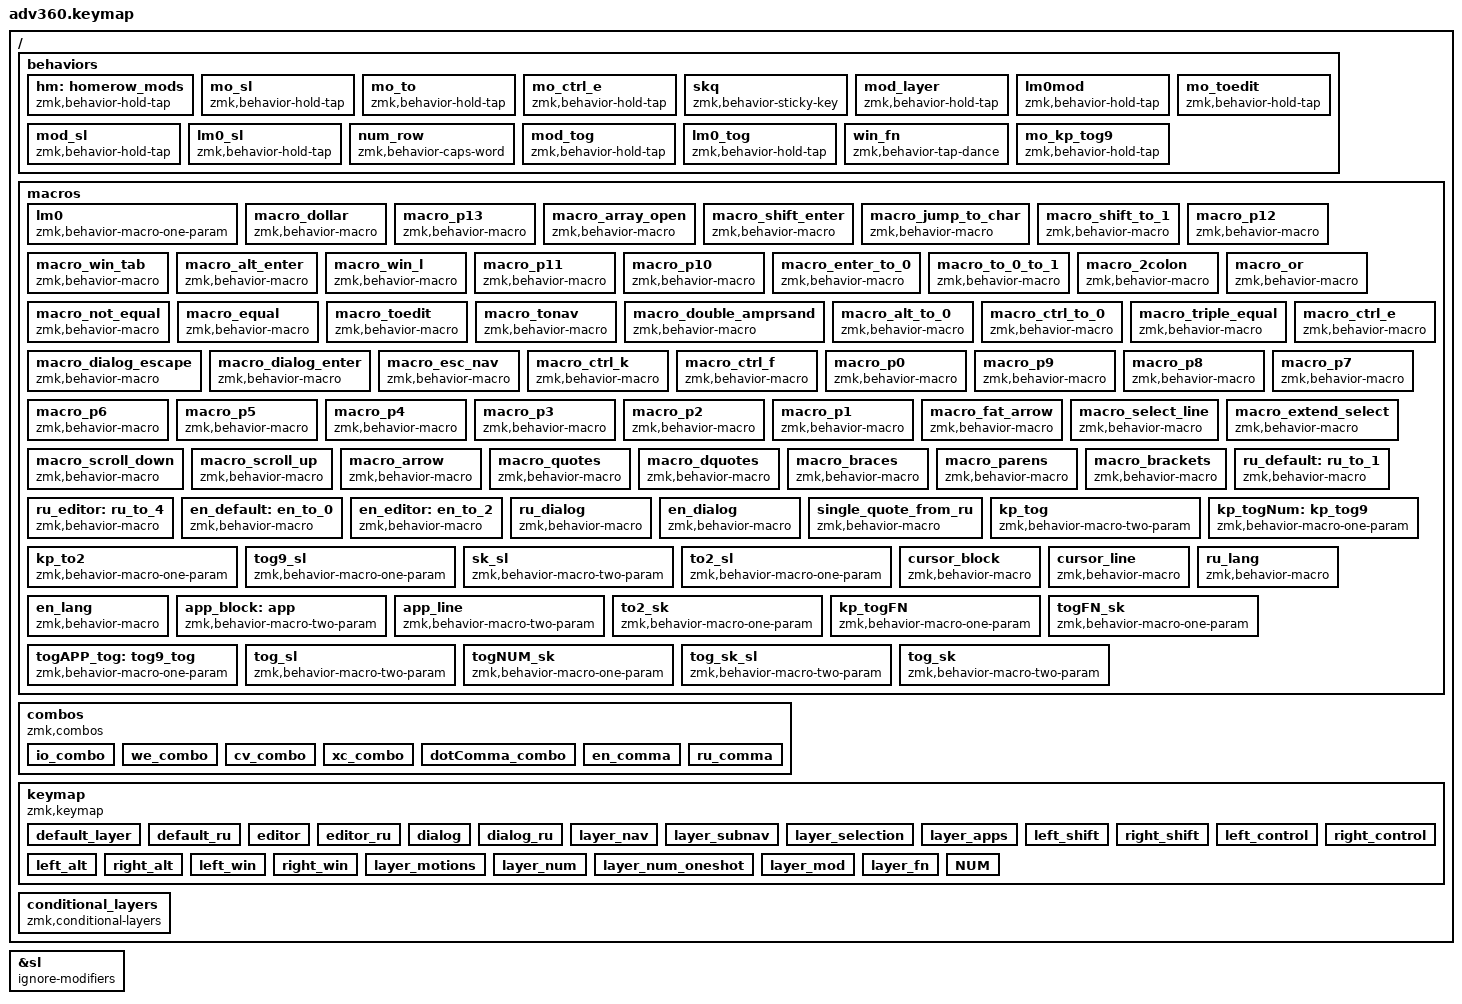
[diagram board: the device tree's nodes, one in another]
/*
 * Copyright (c) 2020 The ZMK Contributors
 *
 * SPDX-License-Identifier: MIT
 */
/* THIS FILE WAS GENERATED!
 *
 * This file was generated automatically. You may or may not want to
 * edit it directly.
 */

#include <dt-bindings/zmk/stp.h>
#include <behaviors.dtsi>
#include <dt-bindings/zmk/backlight.h>
#include <dt-bindings/zmk/bt.h>
#include <dt-bindings/zmk/keys.h>
#include <dt-bindings/zmk/rgb.h>

&sl { ignore-modifiers; };

/ {
    behaviors {
        //#include "macros.dtsi"

        #include "version.dtsi"

        hm: homerow_mods {
            compatible = "zmk,behavior-hold-tap";
            label = "HOMEROW_MODS";
            #binding-cells = <2>;
            tapping-term-ms = <200>;
            quick_tap_ms = <175>;
            flavor = "tap-preferred";
            bindings = <&kp>, <&kp>;
        };

        mo_sl: mo_sl {
            compatible = "zmk,behavior-hold-tap";
            label = "MO_SL";
            #binding-cells = <2>;
            tapping-term-ms = <200>;
            flavor = "tap-preferred";
            bindings = <&mo>, <&sl>;
        };

        mo_to: mo_to {
            compatible = "zmk,behavior-hold-tap";
            label = "MO_TO";
            #binding-cells = <2>;
            tapping-term-ms = <200>;
            quick_tap_ms = <175>;
            flavor = "tap-preferred";
            bindings = <&mo>, <&to>;
        };

        mo_ctrl_e: mo_ctrl_e {
            compatible = "zmk,behavior-hold-tap";
            label = "MO_CTRL_E";
            #binding-cells = <2>;
            tapping-term-ms = <200>;
            quick_tap_ms = <175>;
            flavor = "tap-preferred";
            bindings = <&mo>, <&macro_ctrl_e>;
        };

        skq: skq {
            compatible = "zmk,behavior-sticky-key";
            label = "SKQ";
            bindings = <&kp>;
            #binding-cells = <1>;
            quick-release;
            ignore-modifiers;
            release-after-ms = <1000>;
        };

        mod_layer: mod_layer {
            compatible = "zmk,behavior-hold-tap";
            label = "MOD_LAYER_ENHANCED";
            #binding-cells = <2>;
            tapping-term-ms = <200>;
            quick-tap-ms = <0>;
            flavor = "hold-preferred";
            bindings = <&mo>, <&kp>;

            hold-trigger-key-positions = <71 72 73 74 61 62 63 64 65 70 49 56>;
        };

        lm0mod: lm0mod {
            compatible = "zmk,behavior-hold-tap";
            label = "LM_MOD_0";
            #binding-cells = <2>;
            tapping-term-ms = <200>;
            quick_tap_ms = <175>;
            flavor = "tap-preferred";
            bindings = <&lm0>, <&kp>;
        };

        mo_toedit: mo_toedit {
            compatible = "zmk,behavior-hold-tap";
            label = "MO_TOEDIT";
            #binding-cells = <2>;
            tapping-term-ms = <200>;
            quick_tap_ms = <175>;
            flavor = "tap-preferred";
            bindings = <&mo>, <&macro_toedit>;
        };

        mod_sl: mod_sl {
            compatible = "zmk,behavior-hold-tap";
            label = "MOD_SL";
            bindings = <&kp>, <&sl>;

            #binding-cells = <2>;
            tapping-term-ms = <200>;
            flavor = "tap-preferred";
        };

        lm0_sl: lm0_sl {
            compatible = "zmk,behavior-hold-tap";
            label = "LM0_SL";
            bindings = <&lm0>, <&sl>;

            #binding-cells = <2>;
            flavor = "tap-preferred";
            tapping-term-ms = <200>;
        };

        num_row: num_row {
            compatible = "zmk,behavior-caps-word";
            label = "NUM_ROW";
            #binding-cells = <0>;
            continue-list = <N1 N2 N3 N4 N5 N6 N7 N8 N9 N0>;
            mods = <(MOD_LCTL|MOD_LSFT|MOD_LALT|MOD_LGUI|MOD_RCTL|MOD_RSFT|MOD_RALT|MOD_RGUI)>;
        };

        mod_tog: mod_tog {
            compatible = "zmk,behavior-hold-tap";
            label = "MOD_TOG";
            bindings = <&kp>, <&tog>;

            #binding-cells = <2>;
            tapping-term-ms = <200>;
            flavor = "tap-preferred";
        };

        lm0_tog: lm0_tog {
            compatible = "zmk,behavior-hold-tap";
            label = "LM0_TOG";
            bindings = <&lm0>, <&tog>;

            #binding-cells = <2>;
            tapping-term-ms = <200>;
        };

        win_fn: win_fn {
            compatible = "zmk,behavior-tap-dance";
            label = "WIN_FN";
            #binding-cells = <0>;
            bindings = <&sk LGUI>, <&togFN_sk LGUI>;
        };

        mo_kp_tog9: mo_kp_tog9 {
            compatible = "zmk,behavior-hold-tap";
            label = "MO_KP_TOG9";
            bindings = <&mo>, <&kp_togNum>;

            #binding-cells = <2>;
            tapping-term-ms = <200>;
            flavor = "tap-preferred";
        };
    };

    macros {
        lm0: lm0 {
            compatible = "zmk,behavior-macro-one-param";
            wait-ms = <0>;
            tap-ms = <0>;
            #binding-cells = <1>;
            bindings =
                <&macro_tap>,
                <&to 2>,
                <&macro_press>,
                <&macro_param_1to1 &kp MACRO_PLACEHOLDER>,
                <&macro_pause_for_release>,
                <&macro_release>,
                <&macro_param_1to1 &kp MACRO_PLACEHOLDER>,
                <&macro_tap>,
                <&to 6>;
        };

        macro_dollar: macro_dollar {
            compatible = "zmk,behavior-macro";
            label = "macro_dollar";
            #binding-cells = <0>;
            bindings = <&to 2 &kp LC(LA(N1)) &kp DOLLAR>;
        };

        macro_p13: macro_p13 {
            compatible = "zmk,behavior-macro";
            label = "macro_p13";
            #binding-cells = <0>;
            bindings = <&kp LC(LS(LA(G))) &to 0>;
        };

        macro_array_open: macro_array_open {
            compatible = "zmk,behavior-macro";
            label = "macro_array_open";
            #binding-cells = <0>;
            bindings = <&kp LEFT_BRACKET &kp SINGLE_QUOTE>;
        };

        macro_shift_enter: macro_shift_enter {
            compatible = "zmk,behavior-macro";
            label = "macro_shift_enter";
            #binding-cells = <0>;
            bindings = <&kp LS(ENTER) &to 2>;
        };

        macro_jump_to_char: macro_jump_to_char {
            compatible = "zmk,behavior-macro";
            label = "macro_jump_to_char";
            #binding-cells = <0>;
            bindings = <&kp LC(SEMICOLON)>;
        };

        macro_shift_to_1: macro_shift_to_1 {
            compatible = "zmk,behavior-macro";
            label = "macro_shift_to_1";
            #binding-cells = <0>;
            bindings = <&to 2 &kp LC(LA(NUMBER_1)) &skq LSHFT>;
        };

        macro_p12: macro_p12 {
            compatible = "zmk,behavior-macro";
            label = "macro_p12";
            #binding-cells = <0>;
            bindings = <&kp LA(LC(LS(E))) &to 0>;
        };

        macro_win_tab: macro_win_tab {
            compatible = "zmk,behavior-macro";
            label = "macro_win_tab";
            #binding-cells = <0>;
            bindings = <&kp LC(LA(TAB)) &to 0>;
        };

        macro_alt_enter: macro_alt_enter {
            compatible = "zmk,behavior-macro";
            label = "macro_alt_enter";
            #binding-cells = <0>;
            bindings = <&kp LA(ENTER) &kp ESC>;
        };

        macro_win_l: macro_win_l {
            compatible = "zmk,behavior-macro";
            label = "macro_win_l";
            #binding-cells = <0>;
            bindings = <&kp LG(L) &to 0>;
        };

        macro_p11: macro_p11 {
            compatible = "zmk,behavior-macro";
            label = "macro_p11";
            #binding-cells = <0>;
            bindings = <&kp LA(LC(LS(Z))) &to 6 &kp LA(LC(N0)) &en_lang>;
        };

        macro_p10: macro_p10 {
            compatible = "zmk,behavior-macro";
            label = "macro_p10";
            #binding-cells = <0>;
            bindings = <&kp LC(LS(LA(A))) &to 6 &kp LA(LC(N0)) &en_lang>;
        };

        macro_enter_to_0: macro_enter_to_0 {
            compatible = "zmk,behavior-macro";
            label = "macro_enter_to_0";
            #binding-cells = <0>;
            bindings = <&kp ENTER &tog 0>;
        };

        macro_to_0_to_1: macro_to_0_to_1 {
            compatible = "zmk,behavior-macro";
            label = "macro_to_0_to_1";
            #binding-cells = <0>;
            bindings = <&to 2 &kp LC(LA(NUMBER_1)) &sl 0>;
        };

        macro_2colon: macro_2colon {
            compatible = "zmk,behavior-macro";
            label = "macro_2colon";
            #binding-cells = <0>;
            bindings = <&kp COLON &kp COLON>;
        };

        macro_or: macro_or {
            compatible = "zmk,behavior-macro";
            label = "macro_or";
            #binding-cells = <0>;
            bindings = <&kp PIPE &kp PIPE>;
        };

        macro_not_equal: macro_not_equal {
            compatible = "zmk,behavior-macro";
            label = "macro_not_equal";
            #binding-cells = <0>;
            bindings = <&kp EXCLAMATION &kp EQUAL &kp EQUAL>;
        };

        macro_equal: macro_equal {
            compatible = "zmk,behavior-macro";
            label = "macro_equal";
            #binding-cells = <0>;
            bindings = <&kp SPACE &kp EQUAL &kp SPACE>;
        };

        macro_toedit: macro_toedit {
            compatible = "zmk,behavior-macro";
            label = "macro_toedit";
            #binding-cells = <0>;
            bindings = <&to 2 &kp LC(LA(N1))>;
        };

        macro_tonav: macro_tonav {
            compatible = "zmk,behavior-macro";
            label = "macro_tonav";
            #binding-cells = <0>;
            bindings = <&to 6 &kp LC(LA(N0)) &en_lang>;
        };

        macro_double_amprsand: macro_double_amprsand {
            compatible = "zmk,behavior-macro";
            label = "macro_double_amprsand";
            #binding-cells = <0>;
            bindings = <&kp SPACE &kp AMPERSAND &kp AMPERSAND &kp SPACE>;
        };

        macro_alt_to_0: macro_alt_to_0 {
            compatible = "zmk,behavior-macro";
            label = "macro_alt_to_0";
            #binding-cells = <0>;
            bindings = <&sk LALT &sl 0>;
        };

        macro_ctrl_to_0: macro_ctrl_to_0 {
            compatible = "zmk,behavior-macro";
            label = "macro_ctrl_to_0";
            #binding-cells = <0>;
            bindings = <&sk LCTRL &sl 0>;
        };

        macro_triple_equal: macro_triple_equal {
            compatible = "zmk,behavior-macro";
            label = "macro_triple_equal";
            #binding-cells = <0>;
            bindings = <&kp EQUAL &kp EQUAL &kp EQUAL &kp SPACE>;
        };

        macro_ctrl_e: macro_ctrl_e {
            compatible = "zmk,behavior-macro";
            label = "macro_ctrl_e";
            #binding-cells = <0>;
            bindings = <&kp LC(E) &to 4>;
        };

        macro_dialog_escape: macro_dialog_escape {
            compatible = "zmk,behavior-macro";
            label = "macro_dialog_escape";
            #binding-cells = <0>;
            bindings = <&kp ESCAPE &to 6 &kp LC(LA(N0)) &en_lang>;
        };

        macro_dialog_enter: macro_dialog_enter {
            compatible = "zmk,behavior-macro";
            label = "macro_dialog_enter";
            #binding-cells = <0>;
            bindings = <&kp ENTER &to 6 &kp LC(LA(N0)) &en_lang>;
        };

        macro_esc_nav: macro_esc_nav {
            compatible = "zmk,behavior-macro";
            label = "macro_esc_nav";
            #binding-cells = <0>;
            bindings = <&kp ESCAPE &to 6>;
        };

        macro_ctrl_k: macro_ctrl_k {
            compatible = "zmk,behavior-macro";
            label = "macro_ctrl_k";
            #binding-cells = <0>;
            bindings = <&kp LC(K) &to 2>;
        };

        macro_ctrl_f: macro_ctrl_f {
            compatible = "zmk,behavior-macro";
            label = "macro_ctrl_f";
            #binding-cells = <0>;
            bindings = <&kp LC(F) &to 2>;
        };

        macro_p0: macro_p0 {
            compatible = "zmk,behavior-macro";
            label = "macro_p0";
            #binding-cells = <0>;
            bindings = <&kp LA(LC(LS(B))) &to 6 &kp LC(LA(N0)) &en_lang>;
        };

        macro_p9: macro_p9 {
            compatible = "zmk,behavior-macro";
            label = "macro_p9";
            #binding-cells = <0>;
            bindings = <&kp LC(LS(LA(N4))) &to 0>;
        };

        macro_p8: macro_p8 {
            compatible = "zmk,behavior-macro";
            label = "macro_p8";
            #binding-cells = <0>;
            bindings = <&kp LC(LS(LA(W))) &to 6 &cursor_block &en_lang>;
        };

        macro_p7: macro_p7 {
            compatible = "zmk,behavior-macro";
            label = "macro_p7";
            #binding-cells = <0>;
            bindings = <&kp LC(LS(LA(R))) &to 0>;
        };

        macro_p6: macro_p6 {
            compatible = "zmk,behavior-macro";
            label = "macro_p6";
            #binding-cells = <0>;
            bindings = <&kp LC(LS(LA(F))) &to 0>;
        };

        macro_p5: macro_p5 {
            compatible = "zmk,behavior-macro";
            label = "macro_p5";
            #binding-cells = <0>;
            bindings = <&kp LC(LS(LA(D))) &to 6 &kp LC(LA(N0)) &en_lang>;
        };

        macro_p4: macro_p4 {
            compatible = "zmk,behavior-macro";
            label = "macro_p4";
            #binding-cells = <0>;
            bindings = <&kp LC(LS(LA(S))) &to 6 &kp LA(LC(N0)) &en_lang>;
        };

        macro_p3: macro_p3 {
            compatible = "zmk,behavior-macro";
            label = "macro_p3";
            #binding-cells = <0>;
            bindings = <&kp LC(LS(LA(N5))) &to 0>;
        };

        macro_p2: macro_p2 {
            compatible = "zmk,behavior-macro";
            label = "macro_p2";
            #binding-cells = <0>;
            bindings = <&kp LC(LS(LA(N2))) &to 0>;
        };

        macro_p1: macro_p1 {
            compatible = "zmk,behavior-macro";
            label = "macro_p1";
            #binding-cells = <0>;
            bindings = <&kp LC(LS(LA(N1))) &to 0>;
        };

        macro_fat_arrow: macro_fat_arrow {
            compatible = "zmk,behavior-macro";
            label = "macro_fat_arrow";
            #binding-cells = <0>;
            bindings = <&kp SPACE &kp EQUAL &kp GREATER_THAN &kp SPACE>;
        };

        macro_select_line: macro_select_line {
            compatible = "zmk,behavior-macro";
            label = "macro_select_line";
            #binding-cells = <0>;
            bindings = <&kp HOME &kp HOME &kp LS(END)>;
        };

        macro_extend_select: macro_extend_select {
            compatible = "zmk,behavior-macro";
            label = "macro_extend_select";
            #binding-cells = <0>;
            bindings = <&kp LC(W)>;
        };

        macro_scroll_down: macro_scroll_down {
            compatible = "zmk,behavior-macro";
            label = "macro_scroll_down";
            #binding-cells = <0>;
            bindings = <&kp DOWN_ARROW &kp DOWN_ARROW &kp DOWN_ARROW>;
        };

        macro_scroll_up: macro_scroll_up {
            compatible = "zmk,behavior-macro";
            label = "macro_scroll_up";
            #binding-cells = <0>;
            bindings = <&kp UP &kp UP &kp UP>;
        };

        macro_arrow: macro_arrow {
            compatible = "zmk,behavior-macro";
            label = "macro_arrow";
            #binding-cells = <0>;
            bindings = <&kp MINUS &kp GREATER_THAN>;
        };

        macro_quotes: macro_quotes {
            compatible = "zmk,behavior-macro";
            label = "macro_quotes";
            #binding-cells = <0>;
            bindings = <&kp SQT &kp SQT &kp LEFT>;
        };

        macro_dquotes: macro_dquotes {
            compatible = "zmk,behavior-macro";
            label = "macro_dquotes";
            #binding-cells = <0>;
            bindings = <&kp DQT &kp DQT &kp LEFT>;
        };

        macro_braces: macro_braces {
            compatible = "zmk,behavior-macro";
            label = "macro_braces";
            #binding-cells = <0>;
            bindings = <&kp LBRC &kp RBRC &kp LEFT>;
        };

        macro_parens: macro_parens {
            compatible = "zmk,behavior-macro";
            label = "macro_parens";
            #binding-cells = <0>;
            bindings = <&kp LPAR &kp RPAR &kp LEFT>;
        };

        macro_brackets: macro_brackets {
            compatible = "zmk,behavior-macro";
            label = "macro_brackets";
            #binding-cells = <0>;
            bindings = <&kp LBKT &kp RBKT &kp LEFT>;
        };

        ru_default: ru_to_1 {
            compatible = "zmk,behavior-macro";
            #binding-cells = <0>;
            bindings = <&ru_lang &to 1>;
            label = "RU_TO_1";
        };

        ru_editor: ru_to_4 {
            compatible = "zmk,behavior-macro";
            #binding-cells = <0>;
            bindings = <&ru_lang &to 3 &kp LC(LA(NUMBER_1))>;
            label = "RU_TO_4";
        };

        en_default: en_to_0 {
            compatible = "zmk,behavior-macro";
            #binding-cells = <0>;
            bindings = <&en_lang &to 0>;
            label = "EN_TO_0";
        };

        en_editor: en_to_2 {
            compatible = "zmk,behavior-macro";
            #binding-cells = <0>;
            bindings = <&en_lang &to 2 &kp LC(LA(NUMBER_1))>;
            label = "EN_TO_2";
        };

        ru_dialog: ru_dialog {
            compatible = "zmk,behavior-macro";
            #binding-cells = <0>;
            bindings = <&ru_lang &to 5>;
            label = "RU_DIALOG";
        };

        en_dialog: en_dialog {
            compatible = "zmk,behavior-macro";
            #binding-cells = <0>;
            bindings = <&en_lang &to 4>;
            label = "EN_DIALOG";
        };

        single_quote_from_ru: single_quote_from_ru {
            compatible = "zmk,behavior-macro";
            #binding-cells = <0>;
            bindings = <&kp LC(LS(NUMBER_1)) &kp SINGLE_QUOTE &kp LC(LS(NUMBER_2))>;
            label = "SINGLE_QUOTE_FROM_RU";
        };

        kp_tog: kp_tog {
            compatible = "zmk,behavior-macro-two-param";
            #binding-cells = <2>;
            bindings =
                <&macro_tap>,
                <&macro_param_1to1 &kp MACRO_PLACEHOLDER &macro_param_2to1 &tog MACRO_PLACEHOLDER>;

            label = "KP_TOG";
        };

        kp_togNum: kp_tog9 {
            compatible = "zmk,behavior-macro-one-param";
            #binding-cells = <1>;
            bindings =
                <&macro_tap>,
                <&macro_param_1to1 &kp MACRO_PLACEHOLDER &tog 20>;

            label = "KP_TOG9";
        };

        kp_to2: kp_to2 {
            compatible = "zmk,behavior-macro-one-param";
            #binding-cells = <1>;
            bindings =
                <&macro_tap>,
                <&macro_param_1to1 &kp MACRO_PLACEHOLDER &to 2 &kp LC(LA(N1))>;

            label = "KP_TO2";
        };

        tog9_sl: tog9_sl {
            compatible = "zmk,behavior-macro-one-param";
            #binding-cells = <1>;
            bindings =
                <&macro_tap>,
                <&tog 9 &macro_param_1to1 &sl MACRO_PLACEHOLDER>;

            label = "TOG9_SL";
        };

        sk_sl: sk_sl {
            compatible = "zmk,behavior-macro-two-param";
            #binding-cells = <2>;
            bindings =
                <&macro_press>,
                <&macro_param_1to1 &sk MACRO_PLACEHOLDER>,
                <&macro_wait_time 40>,
                <&macro_param_2to1 &sl MACRO_PLACEHOLDER>;

            label = "SK_SL";
        };

        to2_sl: to2_sl {
            compatible = "zmk,behavior-macro-one-param";
            label = "TO2_SL";
            #binding-cells = <1>;
            bindings = <&cursor_line &to 2 &macro_param_1to1 &sl MACRO_PLACEHOLDER>;
        };

        cursor_block: cursor_block {
            compatible = "zmk,behavior-macro";
            #binding-cells = <0>;
            bindings = <&kp LC(LA(N0))>;
            label = "CURSOR_BLOCK";
        };

        cursor_line: cursor_line {
            compatible = "zmk,behavior-macro";
            #binding-cells = <0>;
            bindings = <&kp LC(LA(N1))>;
            label = "CURSOR_LINE";
        };

        ru_lang: ru_lang {
            compatible = "zmk,behavior-macro";
            #binding-cells = <0>;
            bindings = <&kp LA(LS(N8))>;
            label = "RU_LANG";
        };

        en_lang: en_lang {
            compatible = "zmk,behavior-macro";
            #binding-cells = <0>;
            bindings = <&kp LA(LS(N9))>;
            label = "EN_LANG";
        };

        app_block: app {
            compatible = "zmk,behavior-macro-two-param";
            #binding-cells = <2>;
            bindings = <&skq LS(LA(LCTRL)) &macro_param_1to1 &kp MACRO_PLACEHOLDER &macro_param_2to1 &to MACRO_PLACEHOLDER &en_lang &cursor_block>;
            label = "APP";
        };

        app_line: app_line {
            compatible = "zmk,behavior-macro-two-param";
            #binding-cells = <2>;
            bindings = <&skq LS(LA(LCTRL)) &macro_param_1to1 &kp MACRO_PLACEHOLDER &macro_param_2to1 &to MACRO_PLACEHOLDER>;
            label = "APP_LINE";
        };

        to2_sk: to2_sk {
            compatible = "zmk,behavior-macro-one-param";
            label = "TO2_SK";
            #binding-cells = <1>;
            bindings = <&cursor_line &to 2 &macro_param_1to1 &sk MACRO_PLACEHOLDER>;
        };

        kp_togFN: kp_togFN {
            compatible = "zmk,behavior-macro-one-param";
            #binding-cells = <1>;
            bindings =
                <&macro_tap>,
                <&macro_param_1to1 &kp MACRO_PLACEHOLDER &tog 22>;

            label = "KP_TOGFN";
        };

        togFN_sk: togFN_sk {
            compatible = "zmk,behavior-macro-one-param";
            label = "TOGFN_SK";
            #binding-cells = <1>;
            bindings = <&tog 22 &macro_param_1to1 &sk MACRO_PLACEHOLDER>;
        };

        togAPP_tog: tog9_tog {
            compatible = "zmk,behavior-macro-one-param";
            #binding-cells = <1>;
            bindings = <&tog 9 &macro_param_1to1 &tog MACRO_PLACEHOLDER>;
            label = "TOG9_TOG";
        };

        tog_sl: tog_sl {
            compatible = "zmk,behavior-macro-two-param";
            #binding-cells = <2>;
            bindings =
                <&macro_tap>,
                <&macro_param_1to1 &tog MACRO_PLACEHOLDER &macro_param_2to1 &sl MACRO_PLACEHOLDER>;

            label = "TOG_SL";
        };

        togNUM_sk: togNUM_sk {
            compatible = "zmk,behavior-macro-one-param";
            label = "TOGNUM_SK";
            #binding-cells = <1>;
            bindings = <&tog 20 &macro_param_1to1 &sk MACRO_PLACEHOLDER>;
        };

        tog_sk_sl: tog_sk_sl {
            compatible = "zmk,behavior-macro-two-param";
            #binding-cells = <2>;
            bindings =
                <&macro_tap>,
                <&macro_param_1to1 &tog MACRO_PLACEHOLDER &macro_param_2to1 &sk MACRO_PLACEHOLDER &macro_param_1to1 &sl MACRO_PLACEHOLDER>;

            label = "TOG_SK_SL";
        };

        tog_sk: tog_sk {
            compatible = "zmk,behavior-macro-two-param";
            #binding-cells = <2>;
            bindings =
                <&macro_tap>,
                <&macro_param_1to1 &tog MACRO_PLACEHOLDER &macro_param_2to1 &sk MACRO_PLACEHOLDER>;

            label = "TOG_SK";
        };
    };

    combos {
        compatible = "zmk,combos";

        io_combo {
            bindings = <&macro_win_tab>;
            key-positions = <24 25>;
        };

        we_combo {
            bindings = <&kp LC(TAB)>;
            key-positions = <16 17>;
        };

        cv_combo {
            bindings = <&kp TAB>;
            key-positions = <50 49>;
        };

        xc_combo {
            bindings = <&kp LA(TAB)>;
            key-positions = <48 49>;
        };

        dotComma_combo {
            bindings = <&sk LGUI>;
            key-positions = <56 57>;
        };

        en_comma {
            bindings = <&sk COMMA>;
            key-positions = <56 55>;
            layers = <0 2 4 6>;
        };

        ru_comma {
            bindings = <&kp LS(SLASH)>;
            key-positions = <56 55>;
            layers = <1 3 5>;
        };
    };

    keymap {
        compatible = "zmk,keymap";

        default_layer {
            bindings = <
&kp GRAVE    &kp BACKSLASH    &kp EQUAL        &mod_sl LSHIFT 11  &kp DOLLAR       &kp ASTERISK  &kp F12                                                                        &kp N0        &kp MINUS  &kp LEFT_PARENTHESIS  &mod_sl RSHFT 10  &kp TAB          &kp LS(SLASH)    &kp RIGHT_BRACKET
&ru_default  &kp Q            &kp W            &kp E              &kp R            &kp T         &to 0                                                                          &to 6         &kp Y      &kp U                 &kp I             &kp O            &kp P            &kp LEFT_BRACKET
&en_default  &kp A            &kp S            &kp D              &kp F            &kp G         &mo 21        &trans       &trans               &trans        &trans           &mo 21        &kp H      &kp J                 &kp K             &kp L            &kp SEMI         &kp SINGLE_QUOTE
&mo 21       &kp Z            &kp X            &kp C              &kp V            &kp B                                    &trans               &trans                                       &kp N      &kp M                 &kp COMMA         &kp DOT          &kp FSLH         &mo 21
&trans       &mod_sl LGUI 17  &mod_sl LALT 15  &mod_sl LCTRL 13   &mod_sl LSHFT 9                &lt 18 SPACE  &lt 8 ENTER  &lt 0 LG(LS(S))      &macro_win_l  &mt LGUI ESCAPE  &lt 19 SPACE             &mod_sl RSHFT 9       &mod_sl RCTRL 12  &mod_sl LALT 14  &mod_sl RGUI 16  &trans
            >;
        };

        default_ru {
            bindings = <
&trans  &trans  &trans  &trans  &kp LS(SLASH)  &kp LS(NUMBER_2)  &trans                                      &trans  &trans  &trans  &trans  &trans  &kp LS(N7)  &trans
&trans  &trans  &trans  &trans  &trans         &trans            &trans                                      &trans  &trans  &trans  &trans  &trans  &trans      &trans
&trans  &trans  &trans  &trans  &trans         &trans            &trans  &trans  &trans      &trans  &trans  &trans  &trans  &trans  &trans  &trans  &trans      &trans
&trans  &trans  &trans  &trans  &trans         &trans                            &trans      &trans                  &trans  &trans  &trans  &trans  &trans      &trans
&trans  &trans  &trans  &trans  &trans                           &trans  &trans  &trans      &trans  &trans  &trans          &trans  &trans  &trans  &trans      &trans
            >;
        };

        editor {
            bindings = <
&trans      &trans  &trans  &trans  &trans  &trans  &trans                                            &trans  &trans  &trans  &trans  &trans  &trans  &trans
&ru_editor  &trans  &trans  &trans  &trans  &trans  &trans                                            &trans  &trans  &trans  &trans  &trans  &trans  &trans
&en_editor  &trans  &trans  &trans  &trans  &trans  &trans  &trans  &trans      &trans  &trans        &trans  &trans  &trans  &trans  &trans  &trans  &trans
&trans      &trans  &trans  &trans  &trans  &trans                  &trans      &trans                        &trans  &trans  &trans  &trans  &trans  &trans
&trans      &trans  &trans  &trans  &trans          &trans  &trans  &trans      &trans  &macro_tonav  &trans          &trans  &trans  &trans  &trans  &trans
            >;
        };

        editor_ru {
            bindings = <
&trans  &trans  &trans  &trans  &kp LS(SLASH)  &kp LS(NUMBER_2)  &trans                                            &trans  &trans  &trans  &trans  &trans  &kp LS(N7)  &trans
&trans  &trans  &trans  &trans  &trans         &trans            &trans                                            &trans  &trans  &trans  &trans  &trans  &trans      &trans
&trans  &trans  &trans  &trans  &trans         &trans            &trans  &trans  &trans      &trans  &trans        &trans  &trans  &trans  &trans  &trans  &trans      &trans
&trans  &trans  &trans  &trans  &trans         &trans                            &trans      &trans                        &trans  &trans  &trans  &trans  &trans      &trans
&trans  &trans  &trans  &trans  &trans                           &trans  &trans  &trans      &trans  &macro_tonav  &trans          &trans  &trans  &trans  &trans      &trans
            >;
        };

        dialog {
            bindings = <
&trans      &trans  &trans  &trans  &trans  &trans  &trans                                                                 &trans  &trans  &trans  &trans  &trans  &trans  &trans
&ru_dialog  &trans  &trans  &trans  &trans  &trans  &trans                                                                 &trans  &trans  &trans  &trans  &trans  &trans  &trans
&en_dialog  &trans  &trans  &trans  &trans  &trans  &trans  &trans               &trans      &trans  &trans                &trans  &trans  &trans  &trans  &trans  &trans  &trans
&trans      &trans  &trans  &trans  &trans  &trans                               &trans      &trans                                &trans  &trans  &trans  &trans  &trans  &trans
&trans      &trans  &trans  &trans  &trans          &trans  &macro_dialog_enter  &trans      &trans  &macro_dialog_escape  &trans          &trans  &trans  &trans  &trans  &trans
            >;
        };

        dialog_ru {
            bindings = <
&trans  &trans  &trans  &trans  &trans  &trans  &trans                                      &trans  &trans  &trans  &trans  &trans  &trans  &trans
&trans  &trans  &trans  &trans  &trans  &trans  &trans                                      &trans  &trans  &trans  &trans  &trans  &trans  &trans
&trans  &trans  &trans  &trans  &trans  &trans  &trans  &trans  &trans      &trans  &trans  &trans  &trans  &trans  &trans  &trans  &trans  &trans
&trans  &trans  &trans  &trans  &trans  &trans                  &trans      &trans                  &trans  &trans  &trans  &trans  &trans  &trans
&trans  &trans  &trans  &trans  &trans          &trans  &trans  &trans      &trans  &trans  &trans          &trans  &trans  &trans  &trans  &trans
            >;
        };

        layer_nav {
            bindings = <
&kp LC(TILDE)  &kp_to2 BACKSLASH  &kp_to2 EQUAL   &to2_sl 11      &kp_to2 DOLLAR    &kp_to2 ASTERISK        &kp LC(LA(N7))                                                                 &none            &kp_to2 MINUS  &kp LEFT_PARENTHESIS  &to2_sl 10   &kp_to2 TAB        &kp_to2 LS(SLASH)  &trans
&ru_editor     &kp LC(LA(L))      &kp LC(W)       &kp LC(SLASH)   &kp LA(ENTER)     &kp LC(D)               &macro_jump_to_char                                                            &trans           &kp LC(V)      &kp LC(LS(P))         &kp UP       &kp LC(BACKSPACE)  &kp LC(HOME)       &trans
&en_editor     &kp HOME           &kp LC(TAB)     &lt 7 LC(B)     &kp LS(ENTER)     &kp LC(LA(LEFT_ARROW))  &kp LC(LA(RIGHT_ARROW))  &trans       &trans      &trans  &trans               &trans           &kp LA(N7)     &kp LC(LEFT)          &kp DOWN     &kp LC(RIGHT)      &kp END            &trans
&trans         &kp LS(F10)        &kp LS(DELETE)  &kp LC(INSERT)  &kp LS(INSERT)    &kp LC(LS(U))                                                 &trans      &trans                                        &kp LS(LC(Z))  &kp LC(Z)             &key_repeat  &kp LC(DELETE)     &kp LC(END)        &trans
&trans         &sl 17             &sl 15          &sl 13          &lm0_tog LSHFT 0                          &mo_ctrl_e 18 0          &lt 8 ENTER  &trans      &trans  &lm0mod LGUI ESCAPE  &mo_toedit 19 0                 &lm0_sl LSHIFT 9      &sl 12       &sl 14             &sl 16             &trans
            >;
        };

        layer_subnav {
            bindings = <
&trans  &trans  &trans  &trans  &trans  &trans  &trans                                      &trans  &trans  &trans                &trans              &trans                 &trans       &trans
&trans  &trans  &trans  &trans  &trans  &trans  &trans                                      &trans  &trans  &kp LC(HOME)          &kp LC(LS(COMMA))   &kp LC(END)            &trans       &trans
&trans  &trans  &trans  &trans  &trans  &trans  &trans  &trans  &trans      &trans  &trans  &trans  &trans  &kp LC(LEFT_BRACKET)  &kp LC(LS(PERIOD))  &kp LC(RIGHT_BRACKET)  &kp LC(END)  &trans
&trans  &trans  &trans  &trans  &trans  &trans                  &trans      &trans                  &trans  &kp PAGE_UP           &kp PAGE_DOWN       &none                  &trans       &trans
&trans  &trans  &trans  &trans  &trans          &trans  &trans  &trans      &trans  &trans  &trans          &trans                &trans              &trans                 &trans       &trans
            >;
        };

        layer_selection {
            bindings = <
&kp LA(GRAVE)  &none         &kp LS(ESCAPE)  &kp LA(ENTER)  &kp LA(ENTER)  &kp LC(LS(F))  &none                                                       &none         &none               &kp LS(TAB)       &none              &kp LA(LC(LS(J)))  &none            &none
&none          &kp LC(T)     &macro_p8       &macro_p12     &macro_p7      &macro_p9      &none                                                       &none         &kp LC(C)           &kp LC(LS(Z))     &kp LS(UP)         &kp LS(LA(LC(O)))  &kp BACKSPACE    &kp LC(LA(COMMA))
&none          &kp LS(HOME)  &macro_p4       &macro_p5      &macro_p6      &macro_p13     &none      &none          &none      &none  &none           &none         &kp LS(HOME)        &kp LS(LEFT)      &kp LS(DOWN)       &kp LS(RIGHT)      &kp LS(END)      &none
&none          &macro_p11    &kp LC(X)       &kp LC(C)      &kp LC(V)      &macro_p0                                &none      &none                                &kp LA(LS(INSERT))  &kp LS(LC(LEFT))  &kp LC(LS(RIGHT))  &kp LA(J)          &kp LS(LC(END))  &none
&none          &none         &none           &none          &none                         &kp LCTRL  &kp LC(ENTER)  &none      &none  &kp LS(ESCAPE)  &kp LS(HOME)                      &none             &none              &none              &none            &none
            >;
        };

        layer_apps {
            bindings = <
&kp LA(GRAVE)  &macro_or       &macro_array_open  &kp K_APP       &none          &macro_double_amprsand  &trans                                                    &trans  &none          &none           &none              &none               &none                  &trans
&trans         &kp LC(T)       &app_block W 6     &app_line E 0   &app_line R 0  &app_line T 0           &trans                                                    &trans  &app_line S 0  &app_block U 6  &app_line I 0      &app_line O 0       &app_line P 0          &trans
&trans         &app_block A 6  &app_block S 6     &app_block D 6  &app_line F 0  &app_line G 0           &trans         &trans         &trans      &trans  &trans  &trans  &app_line H 0  &app_line J 0   &app_line K 0      &app_line L 0       &app_line SEMICOLON 0  &trans
&trans         &app_block Z 6  &app_block X 6     &app_block C 6  &app_line V 0  &app_line B 0                                         &trans      &trans                  &app_line N 0  &app_block M 6  &app_line COMMA 0  &app_line PERIOD 0  &app_line SLASH 0      &trans
&trans         &trans          &kp LC(EQUAL)      &kp LC(N0)      &sl 20                                 &kp LC(SPACE)  &kp LC(ENTER)  &trans      &trans  &sl 23  &sl 0                  &sl 20          &kp F12            &kp LC(F5)          &trans                 &trans
            >;
        };

        left_shift {
            bindings = <
&kp LS(GRAVE)     &kp PIPE   &kp PLUS   &macro_fat_arrow  &kp AMPERSAND  &kp PERCENT  &trans                                                            &trans             &none      &none              &togNUM_sk RSHIFT  &kp LS(TAB)  &none          &kp RIGHT_BRACE
&kp LS(N4)        &kp LS(Q)  &kp LS(W)  &kp LS(E)         &kp LS(R)      &kp LS(T)    &trans                                                            &trans             &kp LS(Y)  &kp LS(U)          &kp LS(I)          &kp LS(O)    &kp LS(P)      &kp LEFT_BRACE
&kp LS(NUMBER_6)  &kp LS(A)  &kp LS(S)  &kp LS(D)         &kp LS(F)      &kp LS(G)    &trans         &trans         &trans      &trans  &trans          &trans             &kp LS(H)  &kp LS(J)          &kp LS(K)          &kp LS(L)    &kp LS(SEMI)   &kp LS(SINGLE_QUOTE)
&trans            &kp LS(Z)  &kp LS(X)  &kp LS(C)         &kp LS(V)      &kp LS(B)                                  &trans      &trans                                     &kp LS(N)  &kp LS(M)          &kp LS(COMMA)      &kp LS(DOT)  &kp LS(SLASH)  &trans
&trans            &trans     &kp AT     &kp HASH          &none                       &kp LS(SPACE)  &kp LS(ENTER)  &trans      &trans  &kp LS(ESCAPE)  &togNUM_sk RSHIFT             &togNUM_sk RSHIFT  &sk RCTRL          &sk LALT     &trans         &trans
            >;
        };

        right_shift {
            bindings = <
&kp LS(GRAVE)  &none      &none      &togNUM_sk LSHFT  &none             &none      &trans                                                               &trans         &kp UNDERSCORE  &kp RIGHT_PARENTHESIS  &macro_arrow   &kp LS(LC(ENTER))  &kp EXCLAMATION  &kp RIGHT_BRACE
&trans         &kp LS(Q)  &kp LS(W)  &kp LS(E)         &kp LS(R)         &kp LS(T)  &trans                                                               &trans         &kp LS(Y)       &kp LS(U)              &kp LS(I)      &kp LS(O)          &kp LS(P)        &kp LEFT_BRACE
&trans         &kp LS(A)  &kp LS(S)  &kp LS(D)         &kp LS(F)         &kp LS(G)  &trans            &trans         &trans      &trans  &trans          &trans         &kp LS(H)       &kp LS(J)              &kp LS(K)      &kp LS(L)          &kp LS(SEMI)     &kp LS(SINGLE_QUOTE)
&trans         &kp LS(Z)  &kp LS(X)  &kp LS(C)         &kp LS(V)         &kp LS(B)                                   &trans      &trans                                 &kp LS(N)       &kp LS(M)              &kp LS(COMMA)  &kp LS(DOT)        &kp LS(SLASH)    &trans
&trans         &trans     &sk LALT   &sk LCTRL         &togNUM_sk LSHFT             &togNUM_sk LSHFT  &kp LS(ENTER)  &trans      &trans  &kp LS(ESCAPE)  &kp LS(SPACE)                  &none                  &none          &none              &trans           &trans
            >;
        };

        left_control {
            bindings = <
&kp GRAVE  &kp LC(BACKSLASH)  &kp LC(EQUAL)  &macro_array_open  &macro_double_amprsand  &macro_not_equal  &none                                                                             &none             &none      &none      &none             &none        &none              &kp LC(RIGHT_BRACKET)
&kp HASH   &kp LC(Q)          &kp LC(F4)     &kp LC(LS(E))      &kp LC(R)               &kp LC(T)         &none                                                                             &none             &kp LC(Y)  &kp LC(U)  &kp LC(I)         &kp LC(O)    &kp LC(P)          &kp LC(LEFT_BRACKET)
&kp CARET  &kp LC(A)          &kp LC(S)      &kp LC(D)          &macro_ctrl_f           &kp LC(G)         &none          &kp LS(LC(ESCAPE))  &kp LC(LA(LS(T)))      &trans  &trans          &none             &kp LC(H)  &kp LC(J)  &macro_ctrl_k     &kp LC(L)    &kp LC(SEMICOLON)  &mt LSHFT SINGLE_QUOTE
&trans     &kp LC(Z)          &kp LC(X)      &kp LC(C)          &kp LC(V)               &kp LC(B)                                            &trans                 &trans                                    &kp LC(N)  &kp LC(M)  &kp LC(COMMA)     &kp LC(DOT)  &kp LC(SLASH)      &kp RSHFT
&trans     &trans             &sk RALT       &sk LGUI           &sk_sl LCTRL 0                            &kp LC(SPACE)  &kp LC(ENTER)       &trans                 &trans  &kp LS(ESCAPE)  &togNUM_sk RCTRL             &sk RSHFT  &togNUM_sk RCTRL  &sk RALT     &trans             &trans
            >;
        };

        right_control {
            bindings = <
&kp GRAVE  &none      &none       &none             &none          &none      &kp LS(LA(LC(T)))                                                                     &kp LC(LA(N7))  &kp LC(MINUS)  &macro_triple_equal  &kp LC(LS(P))  &kp LC(TAB)  &kp AT_SIGN        &kp LC(RIGHT_BRACKET)
&kp CARET  &kp LC(Q)  &kp LC(F4)  &kp LC(LS(E))     &kp LC(R)      &kp LC(T)  &none                                                                                 &none           &kp LC(Y)      &kp LC(U)            &kp LC(I)      &kp LC(O)    &kp LC(P)          &kp LC(LEFT_BRACKET)
&kp HASH   &kp LC(A)  &kp LC(S)   &kp LC(D)         &macro_ctrl_f  &kp LC(G)  &none              &kp LS(LC(ESCAPE))  &kp LC(LA(LS(T)))      &trans  &trans          &none           &kp LC(H)      &kp LC(J)            &macro_ctrl_k  &kp LC(L)    &kp LC(SEMICOLON)  &mt LSHFT SINGLE_QUOTE
&trans     &kp LC(Z)  &kp LC(X)   &kp LC(C)         &kp LC(V)      &kp LC(B)                                         &trans                 &trans                                  &kp LC(N)      &kp LC(M)            &kp LC(COMMA)  &kp LC(DOT)  &kp LC(SLASH)      &kp RSHFT
&trans     &trans     &sk LALT    &togNUM_sk LCTRL  &sk LSHFT                 &togNUM_sk LCTRL   &kp LC(ENTER)       &trans                 &trans  &kp LC(ESCAPE)  &kp LC(SPACE)                  &togNUM_sk RCTRL     &sk RGUI       &sk RALT     &trans             &trans
            >;
        };

        left_alt {
            bindings = <
&kp LA(GRAVE)  &kp LA(BACKSLASH)  &kp LA(EQUAL)  &kp HASH   &kp SEMICOLON  &kp ASTERISK  &kp F12                                                                          &kp N0           &none      &none      &none          &none            &none         &kp LA(RIGHT_BRACKET)
&ru_default    &kp LA(Q)          &kp LA(W)      &kp LA(E)  &kp LA(R)      &kp LA(T)     &to 0                                                                            &to 6            &kp LA(Y)  &kp LA(U)  &kp LA(I)      &kp LA(O)        &kp LA(P)     &kp LA(LEFT_BRACKET)
&en_default    &kp LA(A)          &kp LA(S)      &kp LA(D)  &kp LA(F)      &kp LA(G)     &mo 21         &trans         &trans               &trans        &trans          &mo 21           &kp LA(H)  &kp LA(J)  &kp LA(K)      &kp LA(L)        &kp LA(SEMI)  &kp LA(SINGLE_QUOTE)
&mo 21         &kp LA(Z)          &kp LA(X)      &kp LA(C)  &kp LA(V)      &kp LA(B)                                   &trans               &trans                                         &kp LA(N)  &kp LA(M)  &kp LA(COMMA)  &kp LA(DOT)      &kp LA(FSLH)  &mo 21
&trans         &trans             &none          &none      &none                        &kp LA(SPACE)  &kp LA(ENTER)  &lt 0 LG(LS(S))      &macro_win_l  &kp LA(ESCAPE)  &togNUM_sk LALT             &sk RSHFT  &sk RCTRL      &togNUM_sk LALT  &trans        &trans
            >;
        };

        right_alt {
            bindings = <
&kp GRAVE    &none      &none            &none      &none      &none      &kp F12                                                                            &kp N0         &kp LA(MINUS)  &kp LA(LEFT_PARENTHESIS)  &macro_triple_equal  &kp LA(TAB)  &kp COLON     &kp LA(RIGHT_BRACKET)
&ru_default  &kp LA(Q)  &kp LA(W)        &kp LA(E)  &kp LA(R)  &kp LA(T)  &to 0                                                                              &to 6          &kp LA(Y)      &kp LA(U)                 &kp LA(I)            &kp LA(O)    &kp LA(P)     &kp LA(LEFT_BRACKET)
&en_default  &kp LA(A)  &kp LA(S)        &kp LA(D)  &kp LA(F)  &kp LA(G)  &mo 21           &trans         &trans               &trans        &trans          &mo 21         &kp LA(H)      &kp LA(J)                 &kp LA(K)            &kp LA(L)    &kp LA(SEMI)  &kp LA(SINGLE_QUOTE)
&mo 21       &kp LA(Z)  &kp LA(X)        &kp LA(C)  &kp LA(V)  &kp LA(B)                                  &trans               &trans                                       &kp LA(N)      &kp LA(M)                 &kp LA(COMMA)        &kp LA(DOT)  &kp LA(FSLH)  &mo 21
&trans       &trans     &togNUM_sk LALT  &sk LCTRL  &sk LSHFT             &togNUM_sk LALT  &kp LS(ENTER)  &lt 0 LG(LS(S))      &macro_win_l  &kp LA(ESCAPE)  &kp LA(SPACE)                 &sk RSHFT                 &sk RGUI             &sk RALT     &trans        &trans
            >;
        };

        left_win {
            bindings = <
&kp LG(GRAVE)  &kp PERCENT  &kp RIGHT_PARENTHESIS  &macro_fat_arrow  &kp DOUBLE_QUOTES  &kp PIPE   &trans                                                            &trans           &none      &none      &sk LSHFT      &none        &none            &kp RIGHT_BRACE
&trans         &kp LG(Q)    &kp LG(W)              &kp LG(E)         &kp LG(R)          &kp LG(T)  &trans                                                            &trans           &kp LG(Y)  &kp LG(U)  &kp LG(I)      &kp LG(O)    &kp LG(P)        &kp LEFT_BRACE
&trans         &kp LG(A)    &kp LG(S)              &kp LG(D)         &kp LG(F)          &kp LG(G)  &trans         &trans         &trans      &trans  &trans          &trans           &kp LG(H)  &kp LG(J)  &kp LG(K)      &kp LG(L)    &kp LG(SEMI)     &kp LG(SINGLE_QUOTE)
&trans         &kp LG(Z)    &kp LG(X)              &kp LG(C)         &kp LG(V)          &kp LG(B)                                &trans      &trans                                   &kp LG(N)  &kp LG(M)  &kp LG(COMMA)  &kp LG(DOT)  &kp LG(SLASH)    &trans
&trans         &trans       &none                  &none             &none                         &kp LG(SPACE)  &kp LG(ENTER)  &trans      &trans  &kp LG(ESCAPE)  &togNUM_sk RGUI             &sk LSHFT  &sk RCTRL      &sk LALT     &togNUM_sk RGUI  &trans
            >;
        };

        right_win {
            bindings = <
&kp LS(GRAVE)  &none            &none      &none      &none      &none      &trans                                                              &trans         &kp UNDERSCORE  &kp BACKSLASH  &kp LS(LC(ENTER))  &macro_arrow  &kp EXCLAMATION  &kp RIGHT_BRACE
&trans         &kp LG(Q)        &kp LG(W)  &kp LG(E)  &kp LG(R)  &kp LG(T)  &trans                                                              &trans         &kp LG(Y)       &kp LG(U)      &kp LG(I)          &kp LG(O)     &kp LG(P)        &kp LEFT_BRACE
&trans         &kp LG(A)        &kp LG(S)  &kp LG(D)  &kp LG(F)  &kp LG(G)  &trans           &trans         &trans      &trans  &trans          &trans         &kp LG(H)       &kp LG(J)      &kp LG(K)          &kp LG(L)     &kp LG(SEMI)     &kp LG(SINGLE_QUOTE)
&trans         &kp LG(Z)        &kp LG(X)  &kp LG(C)  &kp LG(V)  &kp LG(B)                                  &trans      &trans                                 &kp LG(N)       &kp LG(M)      &kp LG(COMMA)      &kp LG(DOT)   &kp LG(SLASH)    &trans
&trans         &togNUM_sk LGUI  &sk LALT   &sk LCTRL  &sk LSHFT             &togNUM_sk LGUI  &kp LG(ENTER)  &trans      &trans  &kp LG(ESCAPE)  &kp LG(SPACE)                  &none          &none              &none         &trans           &trans
            >;
        };

        layer_motions {
            bindings = <
&trans  &trans       &trans        &trans              &trans       &trans     &trans                                               &trans      &kp LC(LA(N7))  &kp LC(TAB)     &kp LS(LC(ENTER))  &kp LC(LS(LA(T)))  &trans        &trans
&trans  &trans       &kp N8        &kp N9              &trans       &trans     &trans                                               &trans      &kp LC(V)       &kp LC(Z)       &kp UP_ARROW       &kp BACKSPACE      &kp LC(HOME)  &trans
&trans  &hm LGUI N7  &hm LCTRL N5  &hm LSHFT NUMBER_3  &hm LALT N1  &kp ASTRK  &trans  &trans  &trans      &trans  &kp LC(ESCAPE)   &trans      &kp LC(C)       &kp LEFT_ARROW  &kp DOWN_ARROW     &kp RIGHT_ARROW    &kp END       &trans
&trans  &kp N6       &kp NUMBER_4  &kp NUMBER_2        &kp N0       &kp DOT                    &trans      &trans                               &kp LC(LS(Z))   &kp LC(Z)       &none              &none              &kp HOME      &trans
&trans  &trans       &trans        &trans              &trans                  &trans  &trans  &trans      &trans  &mt LGUI ESCAPE  &kp LSHIFT                  &kp PAGE_DOWN   &kp PG_UP          &kp DELETE         &trans        &trans
            >;
        };

        layer_num {
            bindings = <
&none  &kp KP_DIVIDE  &kp KP_EQUAL   &kp N9        &kp KP_MINUS  &kp KP_MULTIPLY  &none                                      &none  &none    &none        &none         &none         &none        &none
&none  &none          &kp NUMBER_3   &kp NUMBER_4  &none         &none            &none                                      &none  &kp F8   &kp F10      &kp N8        &kp F4        &kp F6       &none
&none  &kp DOT        &kp NUMBER_1   &kp NUMBER_2  &kp NUMBER_0  &none            &none   &none   &none      &none  &none    &none  &kp N8   &hm LALT N0  &hm LSHFT N2  &hm LCTRL N4  &hm LGUI N6  &none
&none  &kp DOT        &kp N8         &kp N7        &kp NUMBER_6  &kp BACKSPACE                    &none      &none                  &kp F18  &kp F1       &kp F12       &kp F14       &kp F16      &none
&none  &none          &kp KP_DIVIDE  &kp KP_MINUS  &kp KP_MINUS                   &kp N5  &trans  &none      &none  &tog 19  &none           &kp LSHFT    &kp LCTRL     &kp LALT      &kp LGUI     &none
            >;
        };

        layer_num_oneshot {
            bindings = <
&none  &none    &kp_togNum KP_EQUAL  &kp_togNum N9        &none                &none  &none                                      &none          &none  &none           &none           &none           &none           &none
&none  &none    &kp_togNum NUMBER_3  &kp_togNum NUMBER_4  &kp_togNum N9        &none  &none                                      &none          &none  &kp_togNum F9   &kp_togNum F4   &kp_togNum F3   &none           &none
&none  &kp DOT  &kp_togNum NUMBER_1  &kp_togNum NUMBER_2  &kp_togNum NUMBER_0  &none  &none   &none   &none      &none  &none    &none          &none  &kp_togNum F10  &kp_togNum F12  &kp_togNum F11  &kp_togNum F13  &none
&none  &kp DOT  &kp_togNum N8        &kp_togNum N7        &kp_togNum NUMBER_6  &none                  &none      &none                          &none  &kp_togNum F6   &kp_togNum F7   &kp_togNum F8   &kp_togNum F14  &none
&none  &none    &none                &none                &none                       &kp N5  &trans  &none      &none  &tog 20  &kp_togNum F5         &none           &kp_togNum F2   &kp_togNum F1   &none           &none
            >;
        };

        layer_mod {
            bindings = <
&bl BL_CYCLE    &bt BT_SEL 0   &bt BT_SEL 1   &bt BT_SEL 2   &bt BT_SEL 3   &bt BT_SEL 4   &none                                                               &none                   &none  &trans      &trans           &none  &none        &none
&none           &bt BT_DISC 0  &bt BT_DISC 1  &bt BT_DISC 2  &bt BT_DISC 3  &bt BT_DISC 4  &bootloader                                                         &bootloader             &none  &none       &none            &none  &none        &none
&studio_unlock  &none          &none          &none          &none          &none          &rgb_ug RGB_MEFS_CMD 5  &trans  &bt BT_CLR_ALL      &trans  &trans  &rgb_ug RGB_MEFS_CMD 5  &none  &none       &none            &none  &none        &none
&bootloader     &bootloader    &none          &none          &none          &bt BT_CLR                                     &trans              &trans                                  &none  &bl BL_TOG  &rgb_ug RGB_TOG  &none  &bootloader  &rgb_ug RGB_MEFS_CMD 5
&none           &none          &none          &bt BT_PRV     &bt BT_NXT                    &trans                  &trans  &trans              &trans  &trans  &trans                         &bl BL_DEC  &bl BL_INC       &none  &none        &none
            >;
        };

        layer_fn {
            bindings = <
&none  &none         &none          &none          &none          &none  &none                                               &none  &none  &none      &none      &none     &none     &none
&none  &none         &kp_togFN F3   &kp_togFN F4   &kp_togFN F9   &none  &none                                               &none  &none  &none      &none      &none     &none     &none
&none  &kp_togFN F2  &kp_togFN F11  &kp_togFN F12  &kp_togFN F10  &none  &none         &none    &none      &none  &kp MINUS  &none  &none  &kp LSHFT  &kp LCTRL  &kp LALT  &kp LGUI  &none
&none  &togFN_sk F1  &kp_togFN F8   &kp_togFN F7   &kp_togFN F6   &none                         &none      &none                    &none  &none      &none      &none     &none     &none
&none  &none         &none          &none          &none                 &kp_togFN F5  &tog 23  &none      &none  &tog 23    &none         &none      &none      &none     &none     &none
            >;
        };

        NUM {
            bindings = <
&kp LA(GRAVE)  &none   &none          &none          &none        &none  &trans                                                                        &trans            &kp_togNum LC(LA(N7))  &none               &kp_togNum LC(LS(ENTER))  &kp_togNum LA(TAB)  &kp_togNum BACKSLASH  &trans
&trans         &none   &none          &kp N9         &none        &none  &trans                                                                        &trans            &none                  &none               &kp N8                    &kp BACKSPACE       &none                 &trans
&trans         &kp N7  &kp N5         &kp N3         &kp N1       &none  &trans                &trans           &trans      &trans  &trans             &trans            &none                  &kp N0              &kp N2                    &kp N4              &kp NUMBER_6          &trans
&trans         &none   &none          &none          &none        &none                                         &trans      &trans                                       &none                  &none               &trans                    &trans              &trans                &trans
&trans         &trans  &sk_sl RALT 0  &sk_sl LGUI 0  &tog_sl 0 0         &mo_kp_tog9 18 SPACE  &kp_tog ENTER 0  &trans      &trans  &kp_togNum ESCAPE  &kp_togNum SPACE                         &tog_sk_sl 0 RSHFT  &tog_sk_sl 0 RCTRL        &sk_sl RALT 0       &trans                &trans
            >;
        };
    };

    conditional_layers { compatible = "zmk,conditional-layers"; };
};
